# ESP32-C61 register map
Vendor: ESPRESSIF SYSTEMS (SHANGHAI) CO., LTD.; Series: ESP32 C-Series; File version: 1
CPU: RV32IMAC r0p0, little endian, no MPU, no FPU, 0 interrupt priority bits
Address unit: 32 bits
Registers are 32-bit, read-write, reset 0x0 unless marked. A register's access mark holds for its fields unless they carry their own. Offsets are from the block's base; [hi:lo] are bit positions; {n}, {i} and the like mark numbered series.

## GPIO_EXT — GPIO_EXT Peripheral
Base 0x60091E00
0x00 CLOCK_GATE — Clock Gating Configure Register
  [0] CLK_EN — Clock enable bit of configuration registers for sigma delta modulation.
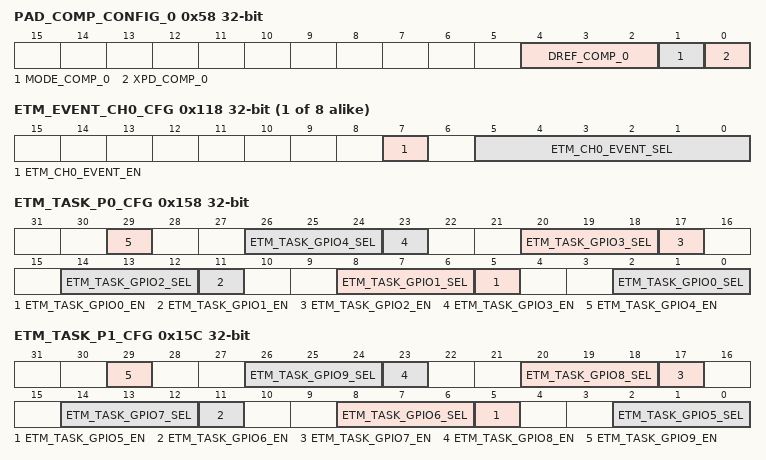
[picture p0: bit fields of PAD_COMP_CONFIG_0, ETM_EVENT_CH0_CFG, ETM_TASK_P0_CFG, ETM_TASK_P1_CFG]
0x58 PAD_COMP_CONFIG_0 — PAD Compare configure Register
  [4:2] DREF_COMP_0 — internal reference voltage tuning bit. 0V to 0.7*VDDPST step 0.1*VDDPST.
  [1] MODE_COMP_0 — 1 to enable external reference from PAD[x]. 0 to enable internal reference, meanwhile PAD[x] can be used as a regular GPIO.
  [0] XPD_COMP_0 — Pad compare enable bit.
0x5C PAD_COMP_FILTER_0 — Zero Detect filter Register
  [31:0] ZERO_DET_FILTER_CNT_0 — Zero Detect filter cycle length
{0x118+4i} ETM_EVENT_CH{i}_CFG (i=0..7) — Etm Config register of Channel{i}
  [7] ETM_CH0_EVENT_EN — Etm event send enable bit.
  [5:0] ETM_CH0_EVENT_SEL — Etm event channel select gpio.
0x158 ETM_TASK_P0_CFG — Etm Configure Register to decide which GPIO been chosen
  [6n+5] ETM_TASK_GPIO{n}_EN (n=0..4) — Enable bit of GPIO response etm task.
  [6n+2:6n] ETM_TASK_GPIO{n}_SEL (n=0..4) — GPIO choose a etm task channel.
0x15C ETM_TASK_P1_CFG — Etm Configure Register to decide which GPIO been chosen
  [6n-25] ETM_TASK_GPIO{n}_EN (n=5..9) — Enable bit of GPIO response etm task.
  [6n-28:6n-30] ETM_TASK_GPIO{n}_SEL (n=5..9) — GPIO choose a etm task channel.
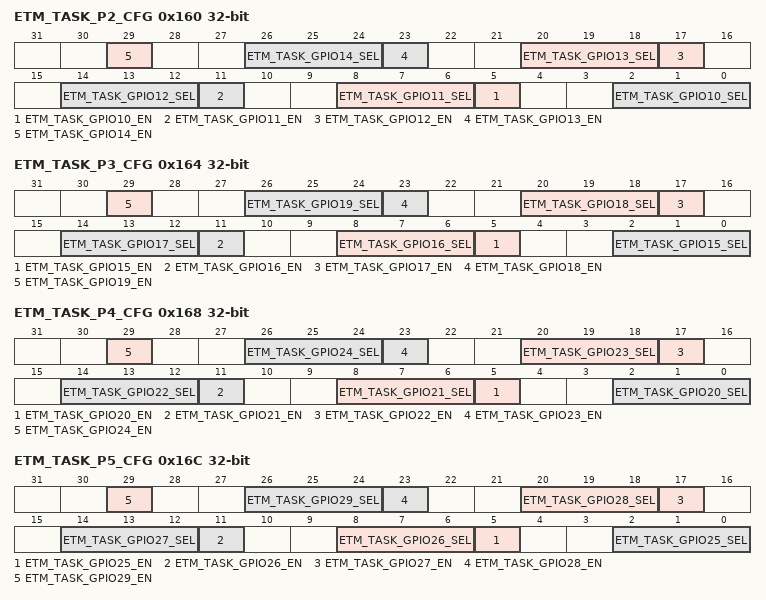
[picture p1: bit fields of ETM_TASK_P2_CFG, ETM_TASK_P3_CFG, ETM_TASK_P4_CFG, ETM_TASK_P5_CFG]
0x160 ETM_TASK_P2_CFG — Etm Configure Register to decide which GPIO been chosen
  [6n-55] ETM_TASK_GPIO{n}_EN (n=10..14) — Enable bit of GPIO response etm task.
  [6n-58:6n-60] ETM_TASK_GPIO{n}_SEL (n=10..14) — GPIO choose a etm task channel.
0x164 ETM_TASK_P3_CFG — Etm Configure Register to decide which GPIO been chosen
  [6n-85] ETM_TASK_GPIO{n}_EN (n=15..19) — Enable bit of GPIO response etm task.
  [6n-88:6n-90] ETM_TASK_GPIO{n}_SEL (n=15..19) — GPIO choose a etm task channel.
0x168 ETM_TASK_P4_CFG — Etm Configure Register to decide which GPIO been chosen
  [6n-115] ETM_TASK_GPIO{n}_EN (n=20..24) — Enable bit of GPIO response etm task.
  [6n-118:6n-120] ETM_TASK_GPIO{n}_SEL (n=20..24) — GPIO choose a etm task channel.
0x16C ETM_TASK_P5_CFG — Etm Configure Register to decide which GPIO been chosen
  [6n-145] ETM_TASK_GPIO{n}_EN (n=25..29) — Enable bit of GPIO response etm task.
  [6n-148:6n-150] ETM_TASK_GPIO{n}_SEL (n=25..29) — GPIO choose a etm task channel.
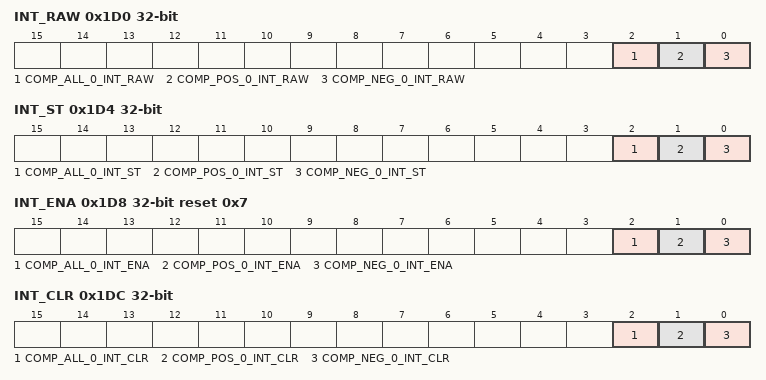
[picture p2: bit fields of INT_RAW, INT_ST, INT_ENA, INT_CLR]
0x1D0 INT_RAW ro — GPIO_EXT interrupt raw register
  [2] COMP_ALL_0_INT_RAW — analog comparator neg or pos edge interrupt raw
  [1] COMP_POS_0_INT_RAW — analog comparator neg edge interrupt raw
  [0] COMP_NEG_0_INT_RAW — analog comparator pos edge interrupt raw
0x1D4 INT_ST ro — GPIO_EXT interrupt masked register
  [2] COMP_ALL_0_INT_ST — analog comparator neg or pos edge interrupt status
  [1] COMP_POS_0_INT_ST — analog comparator neg edge interrupt status
  [0] COMP_NEG_0_INT_ST — analog comparator pos edge interrupt status
0x1D8 INT_ENA reset 0x7 — GPIO_EXT interrupt enable register
  [2] COMP_ALL_0_INT_ENA — analog comparator neg or pos edge interrupt enable
  [1] COMP_POS_0_INT_ENA — analog comparator neg edge interrupt enable
  [0] COMP_NEG_0_INT_ENA — analog comparator pos edge interrupt enable
0x1DC INT_CLR wo — GPIO_EXT interrupt clear register
  [2] COMP_ALL_0_INT_CLR — analog comparator neg or pos edge interrupt clear
  [1] COMP_POS_0_INT_CLR — analog comparator neg edge interrupt clear
  [0] COMP_NEG_0_INT_CLR — analog comparator pos edge interrupt clear
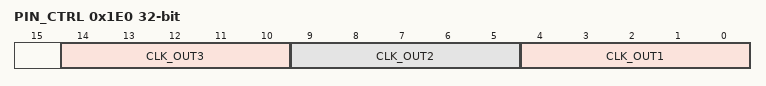
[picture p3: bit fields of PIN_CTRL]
0x1E0 PIN_CTRL — Clock Output Configuration Register
  [14:10] CLK_OUT3 — If you want to output clock for I2S to CLK_OUT_out3, set this register to 0x0. CLK_OUT_out3 can be found in peripheral output signals.
  [9:5] CLK_OUT2 — If you want to output clock for I2S to CLK_OUT_out2, set this register to 0x0. CLK_OUT_out2 can be found in peripheral output signals.
  [4:0] CLK_OUT1 — If you want to output clock for I2S to CLK_OUT_out1, set this register to 0x0. CLK_OUT_out1 can be found in peripheral output signals.
0x1FC VERSION reset 0x2412290 — Version Control Register
  [27:0] DATE — Version control register.
